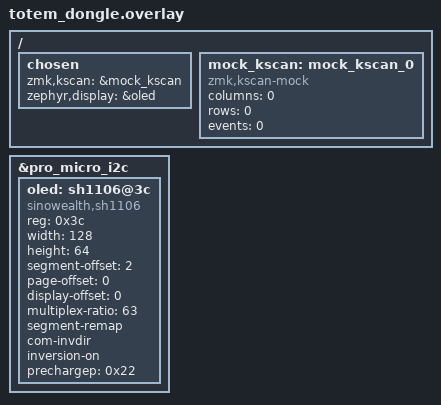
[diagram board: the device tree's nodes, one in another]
/*
 * Copyright (c) 2022 The ZMK Contributors
 *
 * SPDX-License-Identifier: MIT
 */

#include "totem.dtsi"

/ {
    chosen {
        zmk,kscan = &mock_kscan;
        zephyr,display = &oled;
    };

    /*
     * The dongle has no physical key matrix.
     * Key events are received from the split peripherals.
     */
    mock_kscan: mock_kscan_0 {
        compatible = "zmk,kscan-mock";
        columns = <0>;
        rows = <0>;
        events = <0>;
    };
};

/*
 * nice!nano exposes its I2C bus through the Pro Micro interconnect.
 *
 * This configuration assumes:
 *   128x64 OLED
 *   SSD1306 controller
 *   I2C address 0x3C
 */
&pro_micro_i2c {
    status = "okay";

    oled: sh1106@3c {
        compatible = "sinowealth,sh1106";
        reg = <0x3c>;

        width = <128>;
        height = <64>;
        segment-offset = <2>;
        page-offset = <0>;
        display-offset = <0>;
        multiplex-ratio = <63>;

        segment-remap;
        com-invdir;
        inversion-on;
        prechargep = <0x22>;
    };
};
